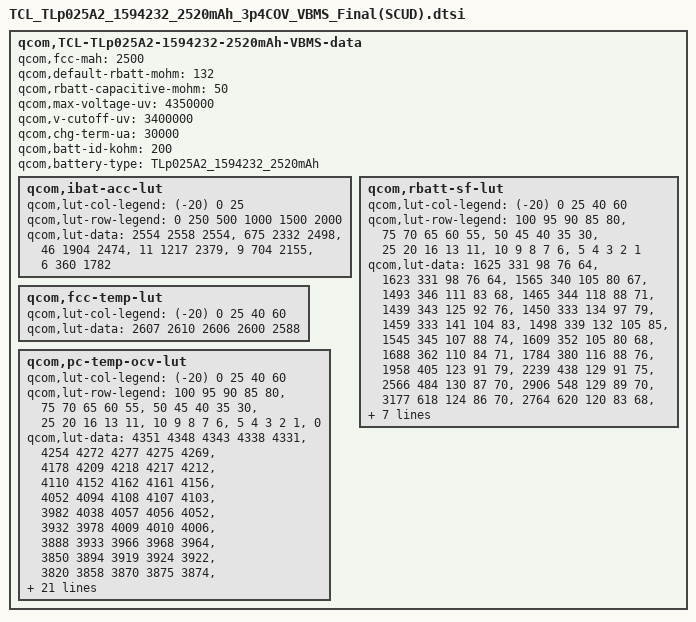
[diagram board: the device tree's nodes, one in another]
 qcom,TCL-TLp025A2-1594232-2520mAh-VBMS-data {
	qcom,fcc-mah = <2500>;
	qcom,default-rbatt-mohm = <132>;
	qcom,rbatt-capacitive-mohm = <50>;
	qcom,max-voltage-uv = <4350000>;
	qcom,v-cutoff-uv = <3400000>;
	qcom,chg-term-ua = <30000>;
	qcom,batt-id-kohm = <200>;
	qcom,battery-type = "TLp025A2_1594232_2520mAh";

	qcom,ibat-acc-lut {
		qcom,lut-col-legend = <(-20) 0 25>;
		qcom,lut-row-legend = <0 250 500 1000 1500 2000>;
		qcom,lut-data = <2554 2558 2554>,
				<675 2332 2498>,
				<46 1904 2474>,
				<11 1217 2379>,
				<9 704 2155>,
				<6 360 1782>;
	};

	qcom,rbatt-sf-lut {
		qcom,lut-col-legend = <(-20) 0 25 40 60>;
		qcom,lut-row-legend = <100 95 90 85 80>,
				<75 70 65 60 55>,
				<50 45 40 35 30>,
				<25 20 16 13 11>,
				<10 9 8 7 6>,
				<5 4 3 2 1>;
		qcom,lut-data = <1625 331 98 76 64>,
				<1623 331 98 76 64>,
				<1565 340 105 80 67>,
				<1493 346 111 83 68>,
				<1465 344 118 88 71>,
				<1439 343 125 92 76>,
				<1450 333 134 97 79>,
				<1459 333 141 104 83>,
				<1498 339 132 105 85>,
				<1545 345 107 88 74>,
				<1609 352 105 80 68>,
				<1688 362 110 84 71>,
				<1784 380 116 88 76>,
				<1958 405 123 91 79>,
				<2239 438 129 91 75>,
				<2566 484 130 87 70>,
				<2906 548 129 89 70>,
				<3177 618 124 86 70>,
				<2764 620 120 83 68>,
				<3068 669 131 89 71>,
				<3288 706 139 93 73>,
				<3542 736 145 97 74>,
				<3915 773 154 100 76>,
				<4404 814 160 101 76>,
				<4988 861 160 97 73>,
				<5547 906 161 96 76>,
				<6389 970 170 104 81>,
				<7914 1061 189 117 93>,
				<10492 1195 230 139 106>,
				<16348 1980 302 189 139>;
	};

	qcom,fcc-temp-lut {
		qcom,lut-col-legend = <(-20) 0 25 40 60>;
		qcom,lut-data = <2607 2610 2606 2600 2588>;
	};

	qcom,pc-temp-ocv-lut {
		qcom,lut-col-legend = <(-20) 0 25 40 60>;
		qcom,lut-row-legend = <100 95 90 85 80>,
				<75 70 65 60 55>,
				<50 45 40 35 30>,
				<25 20 16 13 11>,
				<10 9 8 7 6>,
				<5 4 3 2 1>,
				<0>;
		qcom,lut-data = <4351 4348 4343 4338 4331>,
				<4254 4272 4277 4275 4269>,
				<4178 4209 4218 4217 4212>,
				<4110 4152 4162 4161 4156>,
				<4052 4094 4108 4107 4103>,
				<3982 4038 4057 4056 4052>,
				<3932 3978 4009 4010 4006>,
				<3888 3933 3966 3968 3964>,
				<3850 3894 3919 3924 3922>,
				<3820 3858 3870 3875 3874>,
				<3796 3826 3839 3840 3839>,
				<3776 3800 3815 3817 3816>,
				<3758 3780 3796 3796 3796>,
				<3740 3766 3780 3779 3779>,
				<3724 3752 3768 3764 3757>,
				<3706 3736 3754 3746 3732>,
				<3688 3720 3732 3724 3710>,
				<3670 3707 3700 3692 3678>,
				<3654 3694 3684 3676 3665>,
				<3640 3684 3680 3674 3663>,
				<3632 3680 3679 3672 3662>,
				<3620 3676 3676 3671 3659>,
				<3606 3670 3673 3668 3656>,
				<3589 3659 3666 3660 3644>,
				<3572 3640 3646 3636 3616>,
				<3544 3607 3607 3596 3574>,
				<3508 3558 3554 3542 3522>,
				<3454 3488 3486 3478 3460>,
				<3374 3393 3401 3392 3377>,
				<3246 3258 3276 3262 3240>,
				<3000 3000 3000 3000 3000>;
	};
};
